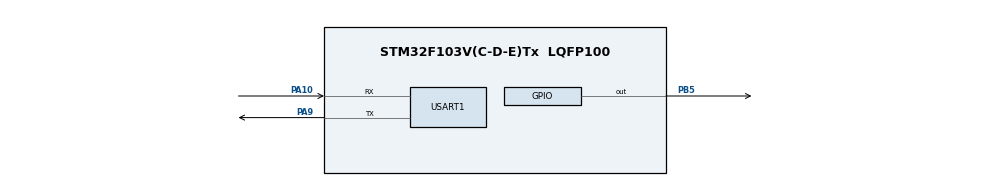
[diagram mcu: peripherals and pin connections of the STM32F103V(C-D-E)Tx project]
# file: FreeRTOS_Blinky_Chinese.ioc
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FREERTOS.Tasks01=blink01,0,128,StartBlink01,Default,NULL,Dynamic,NULL,NULL;blink02,-1,128,StartBlink02,Default,NULL,Dynamic,NULL,NULL
Mcu.Family=STM32F1
Mcu.Name=STM32F103V(C-D-E)Tx
Mcu.Package=LQFP100
NVIC.PriorityGroup=NVIC_PRIORITYGROUP_4
NVIC.TIM6_IRQn=true\:0\:0\:false\:false\:true\:false\:false\:true
NVIC.TimeBase=TIM6_IRQn
NVIC.TimeBaseIP=TIM6
PA10.Mode=Asynchronous
PA10.Signal=USART1_RX
PA13.Mode=Serial_Wire
PA13.Signal=SYS_JTMS-SWDIO
PA14.Mode=Serial_Wire
PA14.Signal=SYS_JTCK-SWCLK
PA9.Mode=Asynchronous
PA9.Signal=USART1_TX
PB5.PinState=GPIO_PIN_SET
PB5.Signal=GPIO_Output
ProjectManager.HeapSize=0x200
ProjectManager.StackSize=0x400
ProjectManager.TargetToolchain=MDK-ARM V5
RCC.APB1Freq_Value=8000000
RCC.APB2Freq_Value=8000000
USART1.VirtualMode=VM_ASYNC
VP_FREERTOS_VS_CMSIS_V1.Mode=CMSIS_V1
VP_SYS_VS_tim6.Mode=TIM6
board=custom

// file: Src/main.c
/* USER CODE BEGIN Header */
/**
  ******************************************************************************
  * @file           : main.c
  * @brief          : Main program body
  ******************************************************************************
  * @attention
  *
  * <h2><center>&copy; Copyright (c) 2022 STMicroelectronics.
  * All rights reserved.</center></h2>
  *
  * This software component is licensed by ST under Ultimate Liberty license
  * SLA0044, the "License"; You may not use this file except in compliance with
  * the License. You may obtain a copy of the License at:
  *                             www.st.com/SLA0044
  *
  ******************************************************************************
  */
/* USER CODE END Header */

#include "main.h"
#include "cmsis_os.h"

/* USER CODE BEGIN Includes */
#include "string.h"

/* USER CODE END Includes */

UART_HandleTypeDef huart1;

osThreadId blink01Handle;
osThreadId blink02Handle;

void SystemClock_Config(void);
static void MX_GPIO_Init(void);
static void MX_USART1_UART_Init(void);
void StartBlink01(void const * argument);
void StartBlink02(void const * argument);

/* USER CODE BEGIN 0 */
uint8_t message_Task01[] = "Hello from Task 1\r\n";
uint8_t message_Task02[] = "Hello from Task 2\r\n";

/* USER CODE END 0 */

int main(void)
{

  /* MCU Configuration--------------------------------------------------------*/

  /* Reset of all peripherals, Initializes the Flash interface and the Systick. */
  HAL_Init();

  /* Configure the system clock */
  SystemClock_Config();

  /* Initialize all configured peripherals */
  MX_GPIO_Init();
  MX_USART1_UART_Init();

  /* Create the thread(s) */
  /* definition and creation of blink01 */
  osThreadDef(blink01, StartBlink01, osPriorityNormal, 0, 128);
  blink01Handle = osThreadCreate(osThread(blink01), NULL);

  /* definition and creation of blink02 */
  osThreadDef(blink02, StartBlink02, osPriorityBelowNormal, 0, 128);
  blink02Handle = osThreadCreate(osThread(blink02), NULL);

  /* Start scheduler */
  osKernelStart();

  /* We should never get here as control is now taken by the scheduler */

  /* Infinite loop */
  while (1)
  {
		// Warning message
		HAL_GPIO_TogglePin(GPIOB,GPIO_PIN_5);
		HAL_Delay(100);

  }
}

void SystemClock_Config(void)
{
  RCC_OscInitTypeDef RCC_OscInitStruct = {0};
  RCC_ClkInitTypeDef RCC_ClkInitStruct = {0};

  /** Initializes the CPU, AHB and APB busses clocks
  */
  RCC_OscInitStruct.OscillatorType = RCC_OSCILLATORTYPE_HSI;
  RCC_OscInitStruct.HSIState = RCC_HSI_ON;
  RCC_OscInitStruct.HSICalibrationValue = RCC_HSICALIBRATION_DEFAULT;
  RCC_OscInitStruct.PLL.PLLState = RCC_PLL_NONE;
  if (HAL_RCC_OscConfig(&RCC_OscInitStruct) != HAL_OK)
  {
    Error_Handler();
  }
  /** Initializes the CPU, AHB and APB busses clocks
  */
  RCC_ClkInitStruct.ClockType = RCC_CLOCKTYPE_HCLK|RCC_CLOCKTYPE_SYSCLK
                              |RCC_CLOCKTYPE_PCLK1|RCC_CLOCKTYPE_PCLK2;
  RCC_ClkInitStruct.SYSCLKSource = RCC_SYSCLKSOURCE_HSI;
  RCC_ClkInitStruct.AHBCLKDivider = RCC_SYSCLK_DIV1;
  RCC_ClkInitStruct.APB1CLKDivider = RCC_HCLK_DIV1;
  RCC_ClkInitStruct.APB2CLKDivider = RCC_HCLK_DIV1;

  if (HAL_RCC_ClockConfig(&RCC_ClkInitStruct, FLASH_LATENCY_0) != HAL_OK)
  {
    Error_Handler();
  }
}

static void MX_USART1_UART_Init(void)
{

  huart1.Instance = USART1;
  huart1.Init.BaudRate = 115200;
  huart1.Init.WordLength = UART_WORDLENGTH_8B;
  huart1.Init.StopBits = UART_STOPBITS_1;
  huart1.Init.Parity = UART_PARITY_NONE;
  huart1.Init.Mode = UART_MODE_TX_RX;
  huart1.Init.HwFlowCtl = UART_HWCONTROL_NONE;
  huart1.Init.OverSampling = UART_OVERSAMPLING_16;
  if (HAL_UART_Init(&huart1) != HAL_OK)
  {
    Error_Handler();
  }

}

static void MX_GPIO_Init(void)
{
  GPIO_InitTypeDef GPIO_InitStruct = {0};

  /* GPIO Ports Clock Enable */
  __HAL_RCC_GPIOA_CLK_ENABLE();
  __HAL_RCC_GPIOB_CLK_ENABLE();

  /*Configure GPIO pin Output Level */
  HAL_GPIO_WritePin(GPIOB, GPIO_PIN_5, GPIO_PIN_SET);

  /*Configure GPIO pin : PB5 */
  GPIO_InitStruct.Pin = GPIO_PIN_5;
  GPIO_InitStruct.Mode = GPIO_MODE_OUTPUT_PP;
  GPIO_InitStruct.Pull = GPIO_NOPULL;
  GPIO_InitStruct.Speed = GPIO_SPEED_FREQ_LOW;
  HAL_GPIO_Init(GPIOB, &GPIO_InitStruct);

}

void StartBlink01(void const * argument)
{

  /* USER CODE BEGIN 5 */
  /* Infinite loop */
  for(;;)
  {
		HAL_UART_Transmit(&huart1 ,message_Task01, strlen((char*)(message_Task01)),HAL_MAX_DELAY);
    osDelay(1000);
  }
	// if for some reason the program breaks from loop, terminate program
	osThreadTerminate(NULL);
  /* USER CODE END 5 */
}

void StartBlink02(void const * argument)
{
  /* USER CODE BEGIN StartBlink02 */
  /* Infinite loop */
  for(;;)
  {
		HAL_UART_Transmit(&huart1 ,message_Task02, strlen((char*)(message_Task02)),HAL_MAX_DELAY);
    osDelay(1000);
  }
	// if for some reason the program breaks from loop, terminate program
  /* USER CODE END StartBlink02 */
}

void HAL_TIM_PeriodElapsedCallback(TIM_HandleTypeDef *htim)
{
  if (htim->Instance == TIM6) {
    HAL_IncTick();
  }
}

void Error_Handler(void)
{
}

/************************ (C) COPYRIGHT STMicroelectronics *****END OF FILE****/
